VERSION ""

NS_ :

BS_:

BU_: VPU IHM BMS

BO_ 3221225472 VECTOR__INDEPENDENT_SIG_MSG: 0 Vector__XXX
 SG_ PAYLOAD_3 : 48|16@1+ (1,0) [0|65535] ""  VPU
 SG_ PAYLOAD_2 : 32|16@1+ (1,0) [0|65535] ""  VPU
 SG_ NewSignal_0012 : 0|8@1+ (1,0) [0|0] "" Vector__XXX

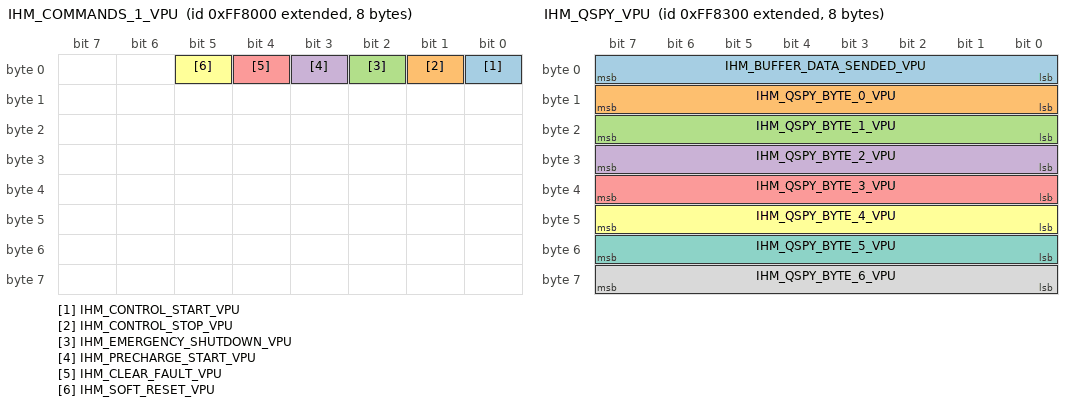
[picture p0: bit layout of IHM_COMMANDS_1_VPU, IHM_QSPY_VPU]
BO_ 2164228096 IHM_COMMANDS_1_VPU: 8 IHM
 SG_ IHM_CONTROL_START_VPU : 0|1@1+ (1,0) [0|1] ""  VPU
 SG_ IHM_CONTROL_STOP_VPU : 1|1@1+ (1,0) [0|1] ""  VPU
 SG_ IHM_EMERGENCY_SHUTDOWN_VPU : 2|1@1+ (1,0) [0|1] ""  VPU
 SG_ IHM_PRECHARGE_START_VPU : 3|1@1+ (1,0) [0|1] "" Vector__XXX
 SG_ IHM_CLEAR_FAULT_VPU : 4|1@1+ (1,0) [0|1] "" Vector__XXX
 SG_ IHM_SOFT_RESET_VPU : 5|1@1+ (1,0) [0|1] "" Vector__XXX

BO_ 2164228352 IHM_SETPOINTS_1_VPU: 8 IHM
 SG_ IHM_SETPOINT_ID_VPU : 0|16@1+ (1,0) [0|65535] ""  VPU
 SG_ IHM_SETPOINT_REQUESTED_VPU : 16|16@1+ (1,-100) [-100|100] ""  VPU

BO_ 2164228608 IHM_MANUAL_EVT_VPU: 8 IHM
 SG_ IHM_COM_SIG_VPU : 0|16@1+ (1,0) [0|65535] ""  VPU
 SG_ IHM_PAYLOAD_VPU : 16|48@1+ (1,0) [0|2] ""  VPU

BO_ 2164228864 IHM_QSPY_VPU: 8 IHM
 SG_ IHM_BUFFER_DATA_SENDED_VPU : 0|8@1+ (1,0) [1|7] ""  VPU
 SG_ IHM_QSPY_BYTE_0_VPU : 8|8@1+ (1,0) [0|255] ""  VPU
 SG_ IHM_QSPY_BYTE_1_VPU : 16|8@1+ (1,0) [0|255] ""  VPU
 SG_ IHM_QSPY_BYTE_2_VPU : 24|8@1+ (1,0) [0|255] ""  VPU
 SG_ IHM_QSPY_BYTE_3_VPU : 32|8@1+ (1,0) [0|255] ""  VPU
 SG_ IHM_QSPY_BYTE_4_VPU : 40|8@1+ (1,0) [0|255] ""  VPU
 SG_ IHM_QSPY_BYTE_5_VPU : 48|8@1+ (1,0) [0|255] ""  VPU
 SG_ IHM_QSPY_BYTE_6_VPU : 56|8@1+ (1,0) [0|255] ""  VPU

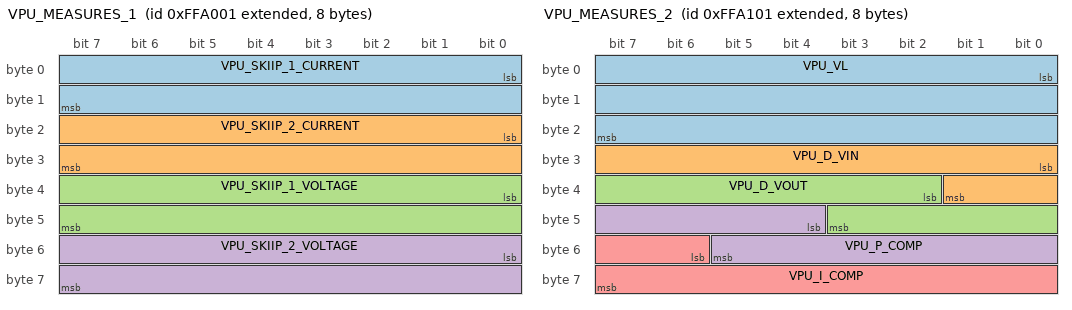
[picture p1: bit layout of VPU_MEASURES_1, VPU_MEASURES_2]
BO_ 2164236289 VPU_MEASURES_1: 8 VPU
 SG_ VPU_SKIIP_1_CURRENT : 0|16@1+ (0.1,-3000) [-3000|3000] ""  IHM
 SG_ VPU_SKIIP_2_CURRENT : 16|16@1+ (0.1,-3000) [-3000|3000] ""  IHM
 SG_ VPU_SKIIP_1_VOLTAGE : 32|16@1+ (0.1,0) [0|2000] ""  IHM
 SG_ VPU_SKIIP_2_VOLTAGE : 48|16@1+ (0.1,0) [0|2000] ""  IHM

BO_ 2164236545 VPU_MEASURES_2: 8 VPU
 SG_ VPU_VL : 0|24@1+ (0.001,-10) [-10|10] "" Vector__XXX
 SG_ VPU_D_VIN : 24|10@1+ (0.001,0) [0|1] "" Vector__XXX
 SG_ VPU_D_VOUT : 34|10@1+ (0.001,0) [0|1] "" Vector__XXX
 SG_ VPU_P_COMP : 44|10@1+ (0.1,-50) [-50|50] "" Vector__XXX
 SG_ VPU_I_COMP : 54|10@1+ (0.1,-50) [-50|50] "" Vector__XXX

BO_ 2164236801 VPU_SETPOINTS_1: 8 VPU
 SG_ VPU_IND_FSBB_CURRENT_SP : 0|16@1+ (1,-2500) [-2500|2500] ""  IHM
 SG_ VPU_FSSB_POWER_SP : 16|16@1+ (1,0) [0|2000] ""  IHM

BO_ 2164237057 VPU_FAULTS_1: 8 VPU
 SG_ VPU_SKIIP1_OVERVOLTAGE : 0|1@1+ (1,0) [0|1] ""  IHM
 SG_ VPU_SKIIP1_OVERCURRENT : 1|1@1+ (1,0) [0|1] ""  IHM
 SG_ VPU_SKIIP1_OVERHEAT : 2|1@1+ (1,0) [0|1] ""  IHM
 SG_ VPU_SKIIP1_HALT : 3|1@1+ (1,0) [0|1] ""  IHM
 SG_ VPU_SKIIP1_ERROR : 4|1@1+ (1,0) [0|1] ""  IHM
 SG_ VPU_SKIIP2_OVERVOLTAGE : 5|1@1+ (1,0) [0|1] ""  IHM
 SG_ VPU_SKIIP2_OVERCURRENT : 6|1@1+ (1,0) [0|1] ""  IHM
 SG_ VPU_SKIIP2_OVERHEAT : 7|1@1+ (1,0) [0|1] ""  IHM
 SG_ VPU_SKIIP2_HALT : 8|1@1+ (1,0) [0|1] ""  IHM
 SG_ VPU_SKIIP2_ERROR : 9|1@1+ (1,0) [0|1] ""  IHM
 SG_ VPU_INDUCTOR_OVERHEAT : 10|1@1+ (1,0) [0|1] ""  IHM
 SG_ VPU_CAPACITOR_OVERHEAT : 11|1@1+ (1,0) [0|1] ""  IHM
 SG_ VPU_SETTLE_TIMEOUT : 12|1@1+ (1,0) [0|1] ""  IHM
 SG_ VPU_CLA_T1_WATCHDOG_TIMEOUT : 13|1@1+ (1,0) [0|1] ""  IHM
 SG_ VPU_CLA_T2_WATCHDOG_TIMEOUT : 14|1@1+ (1,0) [0|1] ""  IHM
 SG_ VPU_EMERGENCY_SHUTDOWN : 15|1@1+ (1,0) [0|1] ""  IHM
 SG_ VPU_SKIIP1_CARDIAC_ARRREST : 16|1@1+ (1,0) [0|1] "" Vector__XXX
 SG_ VPU_SKIIP2_CARDIAC_ARRREST : 17|1@1+ (1,0) [0|1] "" Vector__XXX

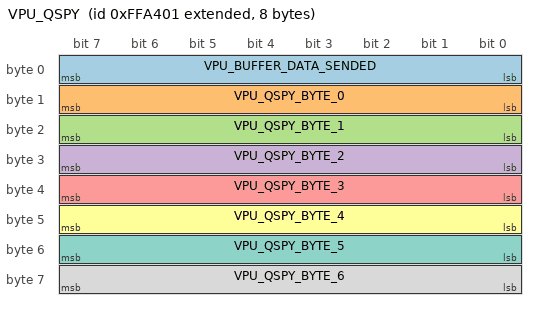
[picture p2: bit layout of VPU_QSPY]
BO_ 2164237313 VPU_QSPY: 8 VPU
 SG_ VPU_BUFFER_DATA_SENDED : 0|8@1+ (1,0) [1|7] ""  IHM
 SG_ VPU_QSPY_BYTE_0 : 8|8@1+ (1,0) [0|255] ""  IHM
 SG_ VPU_QSPY_BYTE_1 : 16|8@1+ (1,0) [0|255] ""  IHM
 SG_ VPU_QSPY_BYTE_2 : 24|8@1+ (1,0) [0|255] ""  IHM
 SG_ VPU_QSPY_BYTE_3 : 32|8@1+ (1,0) [0|255] ""  IHM
 SG_ VPU_QSPY_BYTE_4 : 40|8@1+ (1,0) [0|255] ""  IHM
 SG_ VPU_QSPY_BYTE_5 : 48|8@1+ (1,0) [0|255] ""  IHM
 SG_ VPU_QSPY_BYTE_6 : 56|8@1+ (1,0) [0|255] ""  IHM

BO_ 2164237569 VPU_SYSTEM_STATUS: 8 VPU

CM_ BU_ VPU "Vehicle Propulsion Unit";
CM_ BU_ IHM "Human Machine Interface";
CM_ BU_ BMS "Battery Management System";
BA_DEF_ BU_  "NmStationAddress" INT 0 255;
BA_DEF_  "BusType" STRING ;
BA_DEF_  "ProtocolType" STRING ;
BA_DEF_ BO_  "VFrameFormat" ENUM  "StandardCAN","ExtendedCAN","reserved","J1939PG";
BA_DEF_DEF_  "NmStationAddress" 254;
BA_DEF_DEF_  "BusType" "CAN";
BA_DEF_DEF_  "ProtocolType" "J1939";
BA_DEF_DEF_  "VFrameFormat" "J1939PG";
VAL_ 2164228096 IHM_CONTROL_START_VPU 0 "NO" 1 "YES" ;
VAL_ 2164228096 IHM_CONTROL_STOP_VPU 0 "NO" 1 "YES" ;
VAL_ 2164228096 IHM_EMERGENCY_SHUTDOWN_VPU 0 "NO" 1 "YES" ;
VAL_ 2164228096 IHM_PRECHARGE_START_VPU 0 "NO" 1 "YES" ;
VAL_ 2164228096 IHM_CLEAR_FAULT_VPU 0 "NO" 1 "YES" ;
VAL_ 2164228096 IHM_SOFT_RESET_VPU 0 "NO" 1 "YES" ;
VAL_ 2164228352 IHM_SETPOINT_ID_VPU 0 "IL_CURRENT_SETPOINT" 1 "IO_CURRENT_SETPOINT" 2 "POWER_SETPOINT" ;
